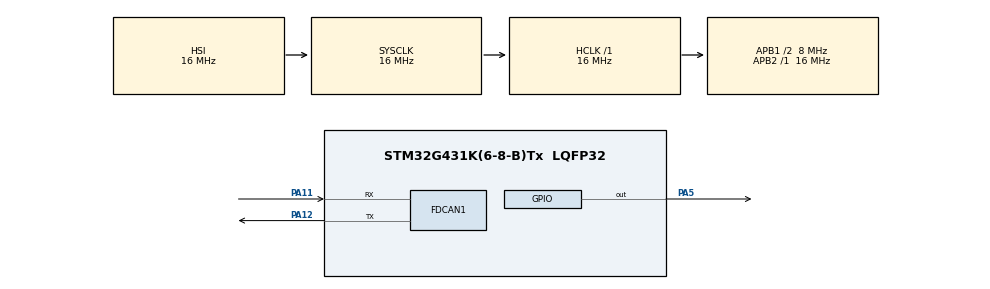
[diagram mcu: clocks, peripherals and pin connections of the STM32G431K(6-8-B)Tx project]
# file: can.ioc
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FDCAN1.AutoRetransmission=ENABLE
FDCAN1.CalculateBaudRateNominal=125000
FDCAN1.CalculateTimeBitNominal=8000
FDCAN1.CalculateTimeQuantumNominal=125.0
FDCAN1.DataSyncJumpWidth=16
FDCAN1.DataTimeSeg1=32
FDCAN1.DataTimeSeg2=5
FDCAN1.FrameFormat=FDCAN_FRAME_FD_NO_BRS
FDCAN1.Mode=FDCAN_MODE_NORMAL
FDCAN1.NominalPrescaler=1
FDCAN1.NominalSyncJumpWidth=8
FDCAN1.NominalTimeSeg1=55
FDCAN1.NominalTimeSeg2=8
FDCAN1.StdFiltersNbr=1
Mcu.Family=STM32G4
Mcu.Name=STM32G431K(6-8-B)Tx
Mcu.Package=LQFP32
NVIC.FDCAN1_IT0_IRQn=true\:0\:0\:false\:false\:true\:true\:true\:true
NVIC.FDCAN1_IT1_IRQn=true\:0\:0\:false\:false\:true\:true\:true\:true
NVIC.PriorityGroup=NVIC_PRIORITYGROUP_4
PA11.Mode=FDCAN_Activate
PA11.Signal=FDCAN1_RX
PA12.Mode=FDCAN_Activate
PA12.Signal=FDCAN1_TX
PA5.Signal=GPIO_Output
PF0-OSC_IN.Mode=HSE-External-Oscillator
PF0-OSC_IN.Signal=RCC_OSC_IN
PF1-OSC_OUT.Mode=HSE-External-Oscillator
PF1-OSC_OUT.Signal=RCC_OSC_OUT
ProjectManager.HeapSize=0x200
ProjectManager.StackSize=0x400
ProjectManager.TargetToolchain=STM32CubeIDE
RCC.AHBFreq_Value=16000000
RCC.APB1CLKDivider=RCC_HCLK_DIV2
RCC.APB1Freq_Value=8000000
RCC.APB1TimFreq_Value=16000000
RCC.APB2Freq_Value=16000000
RCC.APB2TimFreq_Value=16000000
RCC.CortexFreq_Value=16000000
RCC.EXTERNAL_CLOCK_VALUE=12288000
RCC.HCLKFreq_Value=16000000
RCC.HSE_VALUE=8000000
RCC.HSI48_VALUE=48000000
RCC.HSI_VALUE=16000000
RCC.LSE_VALUE=32768
RCC.PLLSourceVirtual=RCC_PLLSOURCE_HSE
RCC.SYSCLKFreq_VALUE=16000000
RCC.USBFreq_Value=32000000
RCC.VCOOutputFreq_Value=64000000
board=custom

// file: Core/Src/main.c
/* USER CODE BEGIN Header */
/**
  ******************************************************************************
  * @file           : main.c
  * @brief          : Main program body
  ******************************************************************************
  * @attention
  *
  * Copyright (c) 2023 STMicroelectronics.
  * All rights reserved.
  *
  * This software is licensed under terms that can be found in the LICENSE file
  * in the root directory of this software component.
  * If no LICENSE file comes with this software, it is provided AS-IS.
  *
  ******************************************************************************
  */
/* USER CODE END Header */
#include "main.h"

FDCAN_HandleTypeDef hfdcan1;

/* USER CODE BEGIN PV */
FDCAN_RxHeaderTypeDef rxHeader;
FDCAN_TxHeaderTypeDef txHeader;
uint8_t canRX[8] = {0,0,0,0,0,0,0,0};
uint8_t canTX[8] = {1,2,3,4,5,6,7,8};

FDCAN_FilterTypeDef canfil;
uint32_t canMailbox;
/* USER CODE END PV */

void SystemClock_Config(void);
static void MX_GPIO_Init(void);
static void MX_FDCAN1_Init(void);

int main(void)
{

  /* MCU Configuration--------------------------------------------------------*/

  /* Reset of all peripherals, Initializes the Flash interface and the Systick. */
  HAL_Init();

  /* Configure the system clock */
  SystemClock_Config();

  /* Initialize all configured peripherals */
  MX_GPIO_Init();
  MX_FDCAN1_Init();
  /* USER CODE BEGIN 2 */

  txHeader.Identifier = 0x11;
  txHeader.IdType = FDCAN_STANDARD_ID;
  txHeader.TxFrameType = FDCAN_DATA_FRAME;
  txHeader.DataLength = FDCAN_DLC_BYTES_8;
  txHeader.ErrorStateIndicator = FDCAN_ESI_ACTIVE;
  txHeader.BitRateSwitch = FDCAN_BRS_OFF;
  txHeader.FDFormat = FDCAN_FD_CAN;
  txHeader.TxEventFifoControl = FDCAN_NO_TX_EVENTS;
  txHeader.MessageMarker = 0;

  /* USER CODE END 2 */

  /* Infinite loop */
  /* USER CODE BEGIN WHILE */
  while (1)
  {

    if(HAL_FDCAN_AddMessageToTxFifoQ(&hfdcan1, &txHeader, canTX) != HAL_OK) {
		  Error_Handler();
	  } else {
		  HAL_GPIO_TogglePin(GPIOA, GPIO_PIN_5);
	  }
	  //printf("1s in while");
	  HAL_Delay(200);
    /* USER CODE END WHILE */

  }
}

void SystemClock_Config(void)
{
  RCC_OscInitTypeDef RCC_OscInitStruct = {0};
  RCC_ClkInitTypeDef RCC_ClkInitStruct = {0};

  /** Configure the main internal regulator output voltage
  */
  HAL_PWREx_ControlVoltageScaling(PWR_REGULATOR_VOLTAGE_SCALE1);

  /** Initializes the RCC Oscillators according to the specified parameters
  * in the RCC_OscInitTypeDef structure.
  */
  RCC_OscInitStruct.OscillatorType = RCC_OSCILLATORTYPE_HSI;
  RCC_OscInitStruct.HSIState = RCC_HSI_ON;
  RCC_OscInitStruct.HSICalibrationValue = RCC_HSICALIBRATION_DEFAULT;
  RCC_OscInitStruct.PLL.PLLState = RCC_PLL_NONE;
  if (HAL_RCC_OscConfig(&RCC_OscInitStruct) != HAL_OK)
  {
    Error_Handler();
  }

  /** Initializes the CPU, AHB and APB buses clocks
  */
  RCC_ClkInitStruct.ClockType = RCC_CLOCKTYPE_HCLK|RCC_CLOCKTYPE_SYSCLK
                              |RCC_CLOCKTYPE_PCLK1|RCC_CLOCKTYPE_PCLK2;
  RCC_ClkInitStruct.SYSCLKSource = RCC_SYSCLKSOURCE_HSI;
  RCC_ClkInitStruct.AHBCLKDivider = RCC_SYSCLK_DIV1;
  RCC_ClkInitStruct.APB1CLKDivider = RCC_HCLK_DIV2;
  RCC_ClkInitStruct.APB2CLKDivider = RCC_HCLK_DIV1;

  if (HAL_RCC_ClockConfig(&RCC_ClkInitStruct, FLASH_LATENCY_0) != HAL_OK)
  {
    Error_Handler();
  }
}

static void MX_FDCAN1_Init(void)
{

  hfdcan1.Instance = FDCAN1;
  hfdcan1.Init.ClockDivider = FDCAN_CLOCK_DIV1;
  hfdcan1.Init.FrameFormat = FDCAN_FRAME_FD_NO_BRS;
  hfdcan1.Init.Mode = FDCAN_MODE_NORMAL;
  hfdcan1.Init.AutoRetransmission = ENABLE;
  hfdcan1.Init.TransmitPause = DISABLE;
  hfdcan1.Init.ProtocolException = DISABLE;
  hfdcan1.Init.NominalPrescaler = 1;
  hfdcan1.Init.NominalSyncJumpWidth = 8;
  hfdcan1.Init.NominalTimeSeg1 = 55;
  hfdcan1.Init.NominalTimeSeg2 = 8;
  hfdcan1.Init.DataPrescaler = 1;
  hfdcan1.Init.DataSyncJumpWidth = 16;
  hfdcan1.Init.DataTimeSeg1 = 32;
  hfdcan1.Init.DataTimeSeg2 = 5;
  hfdcan1.Init.StdFiltersNbr = 1;
  hfdcan1.Init.ExtFiltersNbr = 0;
  hfdcan1.Init.TxFifoQueueMode = FDCAN_TX_FIFO_OPERATION;
  if (HAL_FDCAN_Init(&hfdcan1) != HAL_OK)
  {
    Error_Handler();
  }
  /* USER CODE BEGIN FDCAN1_Init 2 */

  canfil.IdType = FDCAN_STANDARD_ID;
    canfil.FilterIndex = 0;
    canfil.FilterType = FDCAN_FILTER_MASK;
    canfil.FilterConfig = FDCAN_FILTER_TO_RXFIFO0;
    canfil.FilterID1 = 0;
    canfil.FilterID2 = 0;

    if (HAL_FDCAN_ConfigFilter(&hfdcan1, &canfil) != HAL_OK)
    {
      /* Filter configuration Error */
      Error_Handler();
    }

    /* Start the FDCAN module */
    if (HAL_FDCAN_Start(&hfdcan1) != HAL_OK)
    {
      Error_Handler();
    }

    if (HAL_FDCAN_ActivateNotification(&hfdcan1, FDCAN_IT_RX_FIFO0_NEW_MESSAGE, 0) != HAL_OK)
    {
      Error_Handler();
    }
  /* USER CODE END FDCAN1_Init 2 */

}

static void MX_GPIO_Init(void)
{
  GPIO_InitTypeDef GPIO_InitStruct = {0};

  /* GPIO Ports Clock Enable */
  __HAL_RCC_GPIOF_CLK_ENABLE();
  __HAL_RCC_GPIOA_CLK_ENABLE();

  /*Configure GPIO pin Output Level */
  HAL_GPIO_WritePin(GPIOA, GPIO_PIN_5, GPIO_PIN_RESET);

  /*Configure GPIO pin : PA5 */
  GPIO_InitStruct.Pin = GPIO_PIN_5;
  GPIO_InitStruct.Mode = GPIO_MODE_OUTPUT_PP;
  GPIO_InitStruct.Pull = GPIO_NOPULL;
  GPIO_InitStruct.Speed = GPIO_SPEED_FREQ_LOW;
  HAL_GPIO_Init(GPIOA, &GPIO_InitStruct);

}

void Error_Handler(void)
{
  __disable_irq();
  while (1)
  {
  }
}
